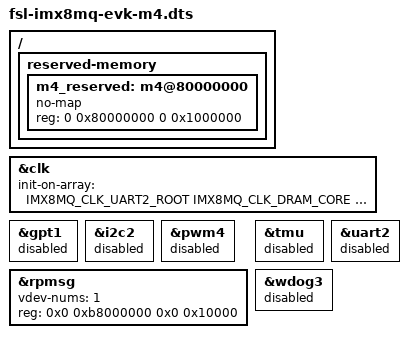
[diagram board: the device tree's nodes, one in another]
/*
 * Copyright 2017 NXP
 *
 * This program is free software; you can redistribute it and/or
 * modify it under the terms of the GNU General Public License
 * as published by the Free Software Foundation; either version 2
 * of the License, or (at your option) any later version.
 *
 * This program is distributed in the hope that it will be useful,
 * but WITHOUT ANY WARRANTY; without even the implied warranty of
 * MERCHANTABILITY or FITNESS FOR A PARTICULAR PURPOSE.  See the
 * GNU General Public License for more details.
 */

#include "fsl-imx8mq-evk.dts"

/ {
	reserved-memory {
		#address-cells = <2>;
		#size-cells = <2>;
		ranges;

		m4_reserved: m4@80000000 {
			no-map;
			reg = <0 0x80000000 0 0x1000000>;
		};

	};
};

&clk {
	init-on-array = <IMX8MQ_CLK_UART2_ROOT
	IMX8MQ_CLK_DRAM_CORE IMX8MQ_CLK_AHB
	IMX8MQ_CLK_NOC IMX8MQ_CLK_NOC_APB
	IMX8MQ_CLK_USB_BUS
	IMX8MQ_CLK_MAIN_AXI IMX8MQ_CLK_A53_CG
	IMX8MQ_CLK_TMU_ROOT
	IMX8MQ_CLK_DRAM_APB IMX8MQ_DRAM_PLL_OUT
	>;
};

&gpt1 {
	status = "disabled";
};

&i2c2 {
	status = "disabled";
};

&pwm4 {
	status = "disabled";
};

&rpmsg{
	/*
	 * 64K for one rpmsg instance:
	 * --0xb8000000~0xb800ffff: pingpong
	 */
	vdev-nums = <1>;
	reg = <0x0 0xb8000000 0x0 0x10000>;
	status = "okay";
};

&tmu {
	status = "disabled";
};

&uart2 {
	status = "disabled";
};

&wdog3{
	status = "disabled";
};
